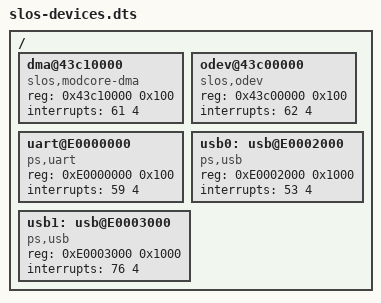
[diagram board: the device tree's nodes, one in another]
// SPDX-License-Identifier: MIT OR Apache-2.0
//
// Copyright (c) 2024 kwangdo.yi<kwangdo.yi@gmail.com>

/dts-v1/;

#include "zynq-7000.dtsi"

/ {
	dma@43c10000 {
		compatible = "slos,modcore-dma";
		reg = <0x43c10000 0x100>;
		interrupts = <61 4>;
	};

	odev@43c00000 {
		compatible = "slos,odev";
		reg = <0x43c00000 0x100>;
		interrupts = <62 4>;
	};

	uart@E0000000 {
		compatible = "ps,uart";
		reg = <0xE0000000 0x100>;
		interrupts = <59 4>;
	};

	usb0:usb@E0002000 {
		compatible = "ps,usb";
		reg = <0xE0002000 0x1000>;
		interrupts = <53 4>;
	};

	usb1:usb@E0003000 {
		compatible = "ps,usb";
		reg = <0xE0003000 0x1000>;
		interrupts = <76 4>;
	};
};

